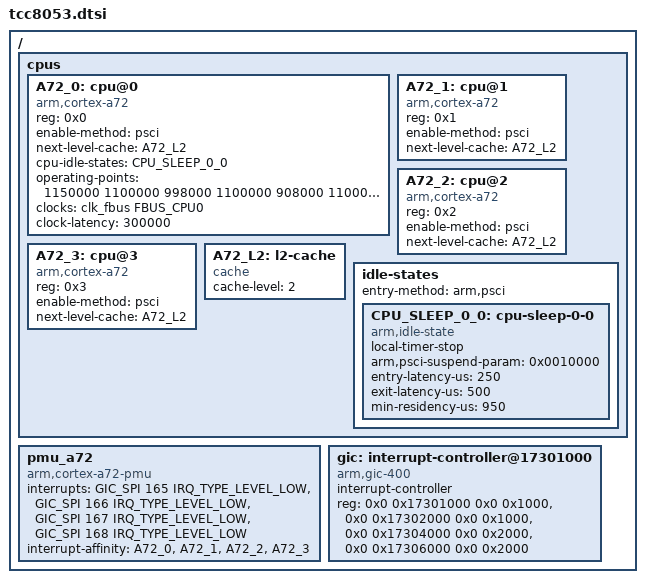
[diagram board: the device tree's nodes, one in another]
// SPDX-License-Identifier: (GPL-2.0-or-later OR MIT)
/*
 * Copyright (C) Telechips Inc.
 * Device tree for Telechips TCC8053 SoC
 */

#include "tcc805x.dtsi"
#include "tcc8050_53-pinctrl.dtsi"

/ {
	cpus {
		#address-cells = <1>;
		#size-cells = <0>;

		A72_0: cpu@0 {
			device_type = "cpu";
			compatible = "arm,cortex-a72";
			reg = <0x0>;
			enable-method = "psci";
			next-level-cache = <&A72_L2>;
			cpu-idle-states = <&CPU_SLEEP_0_0>;
			operating-points = <
				/* kHz    uV */
				/*1302000 1200000*/
				/*1226000 1150000*/
				1150000 1100000
				/*1074000 1050000*/
				998000 1100000
				908000 1100000
			>;

			clocks = <&clk_fbus FBUS_CPU0>;
			clock-names = "cpu0";
			clock-latency = <300000>;
		};

		A72_1: cpu@1 {
			device_type = "cpu";
			compatible = "arm,cortex-a72";
			reg = <0x1>;
			enable-method = "psci";
			next-level-cache = <&A72_L2>;
		};

		A72_2: cpu@2 {
			device_type = "cpu";
			compatible = "arm,cortex-a72";
			reg = <0x2>;
			enable-method = "psci";
			next-level-cache = <&A72_L2>;
		};

		A72_3: cpu@3 {
			device_type = "cpu";
			compatible = "arm,cortex-a72";
			reg = <0x3>;
			enable-method = "psci";
			next-level-cache = <&A72_L2>;
		};

		A72_L2: l2-cache {
			compatible = "cache";
			cache-level = <2>;
		};

		idle-states {
			entry-method = "arm,psci";

			CPU_SLEEP_0_0: cpu-sleep-0-0 {
				compatible = "arm,idle-state";
				local-timer-stop;
				arm,psci-suspend-param = <0x0010000>;
				entry-latency-us = <250>;
				exit-latency-us = <500>;
				min-residency-us = <950>;
			};
		};
	};

	pmu_a72 {
		compatible = "arm,cortex-a72-pmu";
		interrupts = <GIC_SPI 165 IRQ_TYPE_LEVEL_LOW>,
			     <GIC_SPI 166 IRQ_TYPE_LEVEL_LOW>,
			     <GIC_SPI 167 IRQ_TYPE_LEVEL_LOW>,
			     <GIC_SPI 168 IRQ_TYPE_LEVEL_LOW>;
		interrupt-affinity = <&A72_0>,
				     <&A72_1>,
				     <&A72_2>,
				     <&A72_3>;
	};

	gic: interrupt-controller@17301000 {
		compatible = "arm,gic-400";
		#interrupt-cells = <3>;
		#address-cells = <0>;
		interrupt-controller;
		reg = <0x0 0x17301000 0x0 0x1000>,
		      <0x0 0x17302000 0x0 0x1000>,
		      <0x0 0x17304000 0x0 0x2000>,
		      <0x0 0x17306000 0x0 0x2000>;
	};
};
